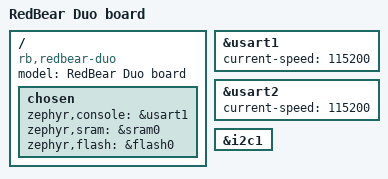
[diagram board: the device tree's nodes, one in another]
/*
 * Copyright (c) 2017 Jérôme Guéry
 *
 * SPDX-License-Identifier: Apache-2.0
 */

/dts-v1/;
#include <st/stm32f205.dtsi>

/ {
	model = "RedBear Duo board";
	compatible = "rb,redbear-duo";

	chosen {
		zephyr,console = &usart1;
		zephyr,sram = &sram0;
		zephyr,flash = &flash0;
	};
};

&usart1 {
	current-speed = <115200>;
	status = "ok";
};

&usart2 {
	current-speed = <115200>;
	status = "ok";
};

&i2c1 {
	status = "ok";
};
